# WE2_S_NS register map
Vendor: ARM Ltd.; Series: ARMv8.1-M Mainline; File version: 1.0
CPU: CM55 r1p1, little endian, MPU, FPU, double-precision FPU, DSP, VTOR, 3 interrupt priority bits
Registers are 32-bit, read-write, reset 0x0 unless marked. A register's access mark holds for its fields unless they carry their own. Offsets are from the block's base; [hi:lo] are bit positions; {n}, {i} and the like mark numbered series.

## SYS_NVIC — Nested Vectored Interrupt Controller
Base 0xE000E100
Same registers: SYS_NVIC_NS 0xE002E100
{0x0+4i} NVIC_ISER{i} (i=0..15)
  [31:0] SETENA — Interrupt set-enable bits. For SETENA[m] in NVIC_ISERn, allows interrupt 32n+m to be accessed
{0x80+4i} NVIC_ICER{i} (i=0..15)
  [31:0] CLRENA — Interrupt clear-enable bits. For SETENA[m] in NVIC_ICERn, allows interrupt 32n + m to be accessed
{0x100+4i} NVIC_ISPR{i} (i=0..15)
  [31:0] SETPEND — Interrupt set-pending bits. For SETPEND[m] in NVIC_ISPRn, allows interrupt 32n + m to be accessed
{0x180+4i} NVIC_ICPR{i} (i=0..15)
  [31:0] CLRPEND — Interrupt clear-pending bits
{0x200+4i} NVIC_IABR{i} (i=0..15)
  [31:0] ACTIVE — Active state bits. For ACTIVE[m] in NVIC_IABRn, indicates the active state for interrupt 32n+m
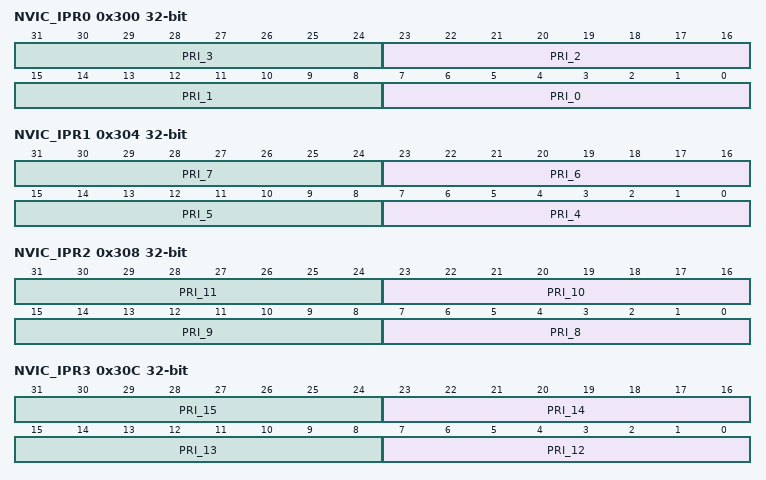
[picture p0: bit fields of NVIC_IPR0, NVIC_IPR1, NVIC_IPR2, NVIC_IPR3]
0x300 NVIC_IPR0
  [8n+7:8n] PRI_{n} (n=0..3)
0x304 NVIC_IPR1
  [8n-25:8n-32] PRI_{n} (n=4..7)
0x308 NVIC_IPR2
  [8n-57:8n-64] PRI_{n} (n=8..11)
0x30C NVIC_IPR3
  [8n-89:8n-96] PRI_{n} (n=12..15)
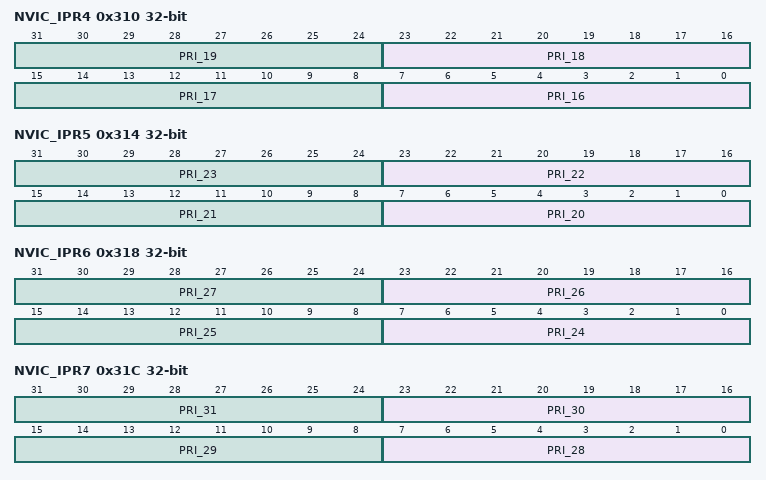
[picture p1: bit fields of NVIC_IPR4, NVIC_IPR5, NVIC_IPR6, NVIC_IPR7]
0x310 NVIC_IPR4
  [8n-121:8n-128] PRI_{n} (n=16..19)
0x314 NVIC_IPR5
  [8n-153:8n-160] PRI_{n} (n=20..23)
0x318 NVIC_IPR6
  [8n-185:8n-192] PRI_{n} (n=24..27)
0x31C NVIC_IPR7
  [8n-217:8n-224] PRI_{n} (n=28..31)
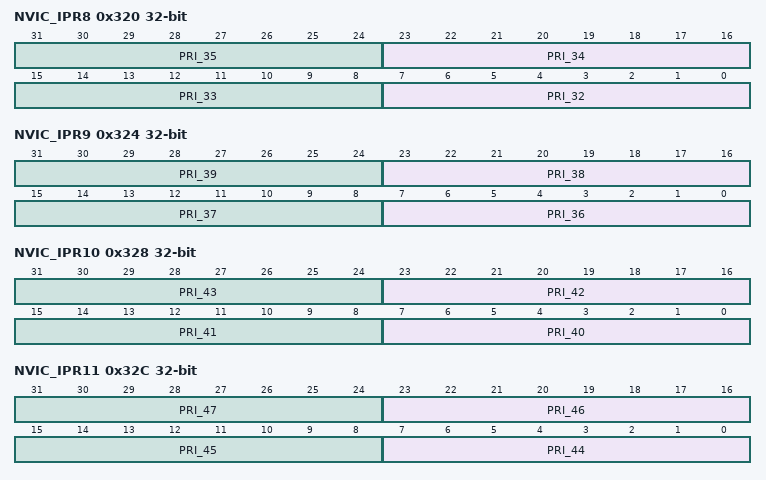
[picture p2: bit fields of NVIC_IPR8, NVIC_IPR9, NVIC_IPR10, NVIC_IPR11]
0x320 NVIC_IPR8
  [8n-249:8n-256] PRI_{n} (n=32..35)
0x324 NVIC_IPR9
  [8n-281:8n-288] PRI_{n} (n=36..39)
0x328 NVIC_IPR10
  [8n-313:8n-320] PRI_{n} (n=40..43)
0x32C NVIC_IPR11
  [8n-345:8n-352] PRI_{n} (n=44..47)
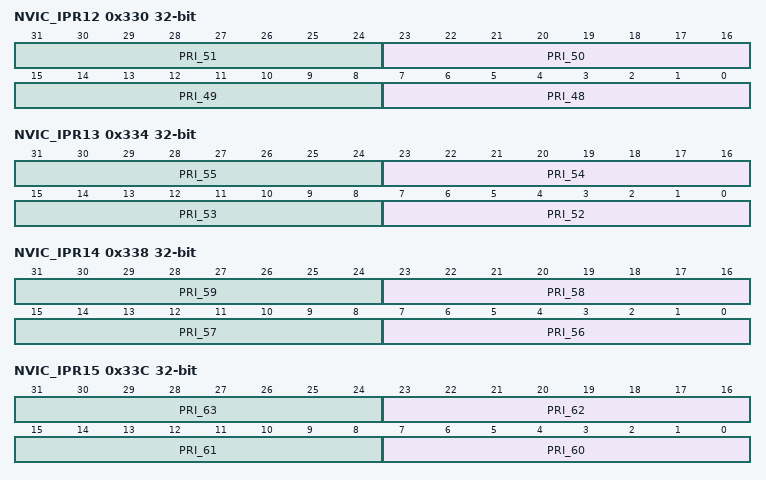
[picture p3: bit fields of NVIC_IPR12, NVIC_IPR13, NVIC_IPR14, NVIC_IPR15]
0x330 NVIC_IPR12
  [8n-377:8n-384] PRI_{n} (n=48..51)
0x334 NVIC_IPR13
  [8n-409:8n-416] PRI_{n} (n=52..55)
0x338 NVIC_IPR14
  [8n-441:8n-448] PRI_{n} (n=56..59)
0x33C NVIC_IPR15
  [8n-473:8n-480] PRI_{n} (n=60..63)
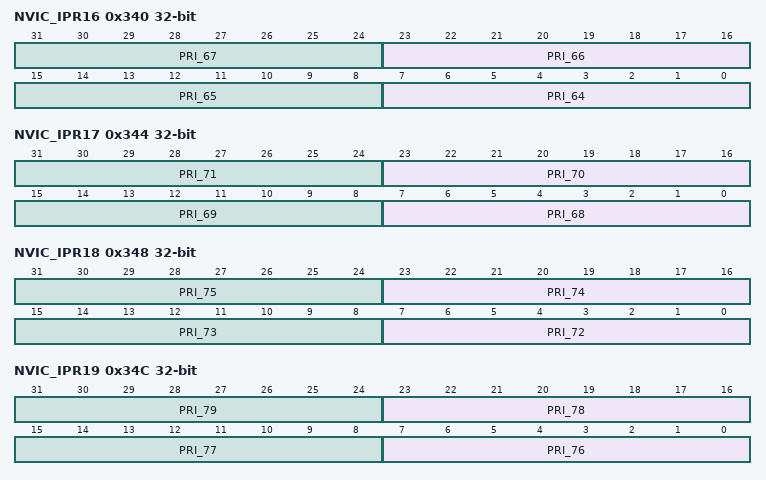
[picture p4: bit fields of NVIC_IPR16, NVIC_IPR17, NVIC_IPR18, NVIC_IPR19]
0x340 NVIC_IPR16
  [8n-505:8n-512] PRI_{n} (n=64..67)
0x344 NVIC_IPR17
  [8n-537:8n-544] PRI_{n} (n=68..71)
0x348 NVIC_IPR18
  [8n-569:8n-576] PRI_{n} (n=72..75)
0x34C NVIC_IPR19
  [8n-601:8n-608] PRI_{n} (n=76..79)
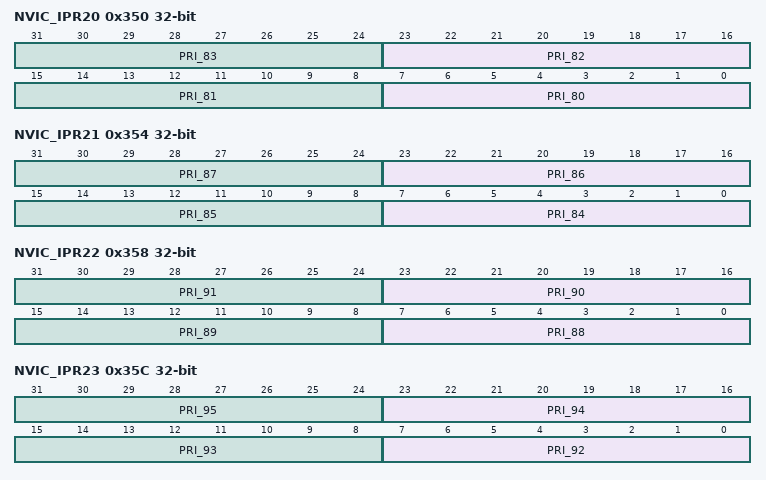
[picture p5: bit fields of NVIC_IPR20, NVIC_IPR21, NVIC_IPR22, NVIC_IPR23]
0x350 NVIC_IPR20
  [8n-633:8n-640] PRI_{n} (n=80..83)
0x354 NVIC_IPR21
  [8n-665:8n-672] PRI_{n} (n=84..87)
0x358 NVIC_IPR22
  [8n-697:8n-704] PRI_{n} (n=88..91)
0x35C NVIC_IPR23
  [8n-729:8n-736] PRI_{n} (n=92..95)
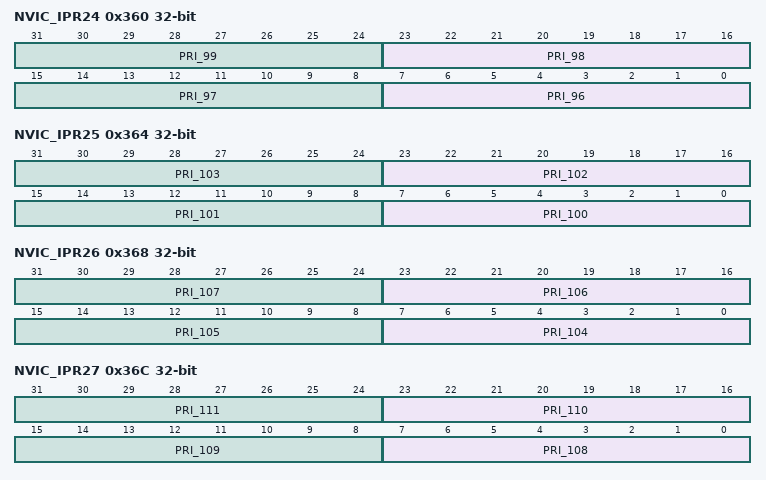
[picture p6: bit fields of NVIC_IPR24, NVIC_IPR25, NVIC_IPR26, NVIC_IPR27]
0x360 NVIC_IPR24
  [8n-761:8n-768] PRI_{n} (n=96..99)
0x364 NVIC_IPR25
  [8n-793:8n-800] PRI_{n} (n=100..103)
0x368 NVIC_IPR26
  [8n-825:8n-832] PRI_{n} (n=104..107)
0x36C NVIC_IPR27
  [8n-857:8n-864] PRI_{n} (n=108..111)
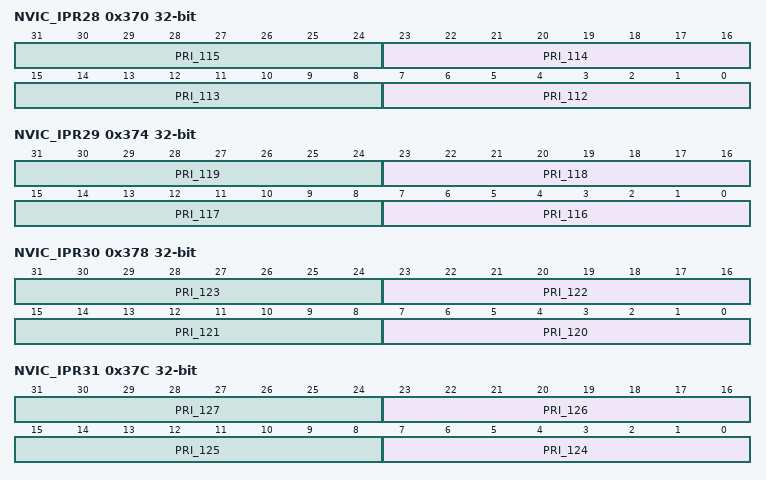
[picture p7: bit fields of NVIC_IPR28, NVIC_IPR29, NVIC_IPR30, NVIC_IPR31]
0x370 NVIC_IPR28
  [8n-889:8n-896] PRI_{n} (n=112..115)
0x374 NVIC_IPR29
  [8n-921:8n-928] PRI_{n} (n=116..119)
0x378 NVIC_IPR30
  [8n-953:8n-960] PRI_{n} (n=120..123)
0x37C NVIC_IPR31
  [8n-985:8n-992] PRI_{n} (n=124..127)
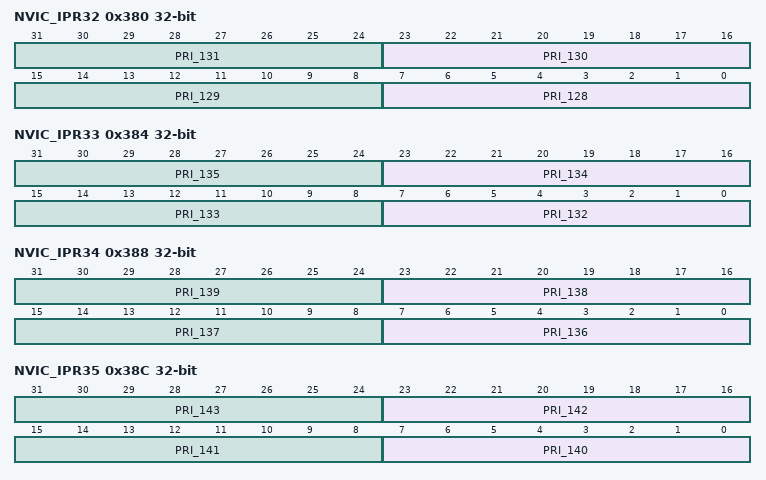
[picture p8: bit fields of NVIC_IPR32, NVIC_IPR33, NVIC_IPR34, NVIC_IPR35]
0x380 NVIC_IPR32
  [8n-1017:8n-1024] PRI_{n} (n=128..131)
0x384 NVIC_IPR33
  [8n-1049:8n-1056] PRI_{n} (n=132..135)
0x388 NVIC_IPR34
  [8n-1081:8n-1088] PRI_{n} (n=136..139)
0x38C NVIC_IPR35
  [8n-1113:8n-1120] PRI_{n} (n=140..143)
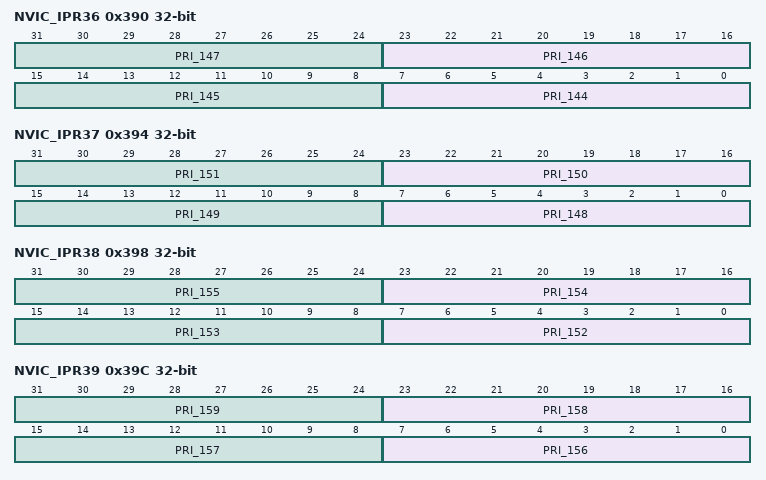
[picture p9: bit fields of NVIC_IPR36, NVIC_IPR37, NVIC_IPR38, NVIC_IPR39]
0x390 NVIC_IPR36
  [8n-1145:8n-1152] PRI_{n} (n=144..147)
0x394 NVIC_IPR37
  [8n-1177:8n-1184] PRI_{n} (n=148..151)
0x398 NVIC_IPR38
  [8n-1209:8n-1216] PRI_{n} (n=152..155)
0x39C NVIC_IPR39
  [8n-1241:8n-1248] PRI_{n} (n=156..159)
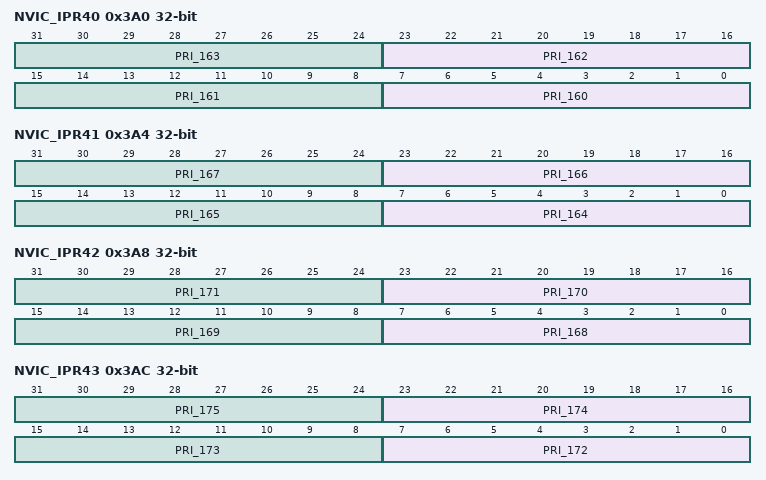
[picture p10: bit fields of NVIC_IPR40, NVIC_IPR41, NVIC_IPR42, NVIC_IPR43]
0x3A0 NVIC_IPR40
  [8n-1273:8n-1280] PRI_{n} (n=160..163)
0x3A4 NVIC_IPR41
  [8n-1305:8n-1312] PRI_{n} (n=164..167)
0x3A8 NVIC_IPR42
  [8n-1337:8n-1344] PRI_{n} (n=168..171)
0x3AC NVIC_IPR43
  [8n-1369:8n-1376] PRI_{n} (n=172..175)
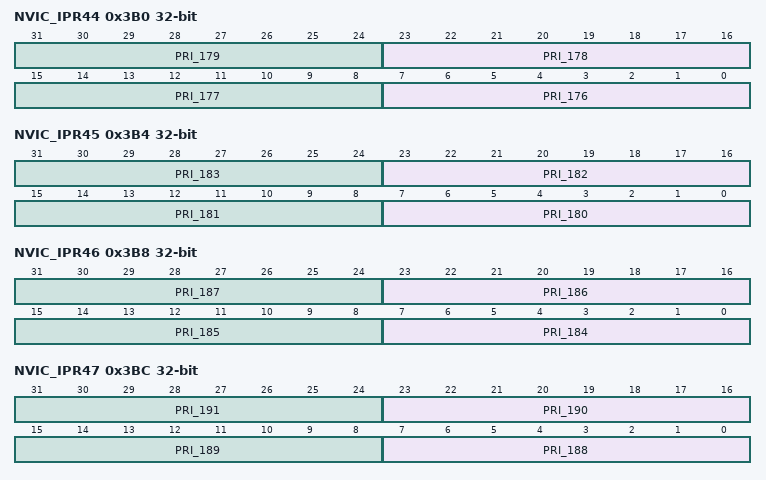
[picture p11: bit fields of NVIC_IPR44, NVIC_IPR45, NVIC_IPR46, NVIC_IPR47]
0x3B0 NVIC_IPR44
  [8n-1401:8n-1408] PRI_{n} (n=176..179)
0x3B4 NVIC_IPR45
  [8n-1433:8n-1440] PRI_{n} (n=180..183)
0x3B8 NVIC_IPR46
  [8n-1465:8n-1472] PRI_{n} (n=184..187)
0x3BC NVIC_IPR47
  [8n-1497:8n-1504] PRI_{n} (n=188..191)
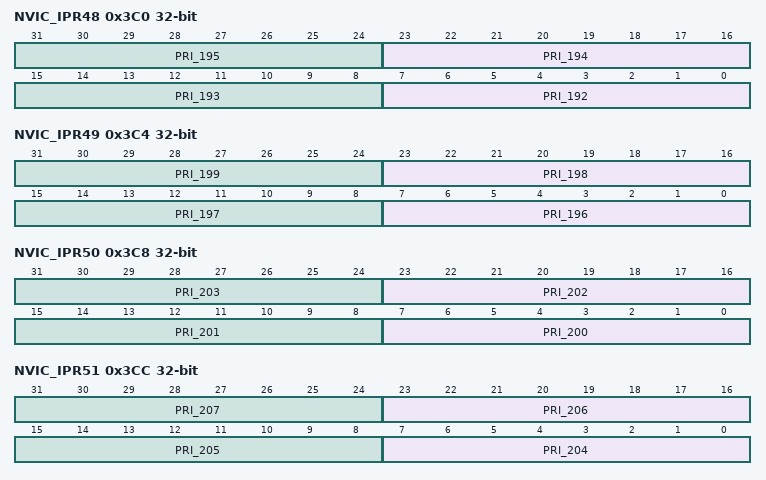
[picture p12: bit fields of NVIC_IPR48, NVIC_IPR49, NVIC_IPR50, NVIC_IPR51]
0x3C0 NVIC_IPR48
  [8n-1529:8n-1536] PRI_{n} (n=192..195)
0x3C4 NVIC_IPR49
  [8n-1561:8n-1568] PRI_{n} (n=196..199)
0x3C8 NVIC_IPR50
  [8n-1593:8n-1600] PRI_{n} (n=200..203)
0x3CC NVIC_IPR51
  [8n-1625:8n-1632] PRI_{n} (n=204..207)
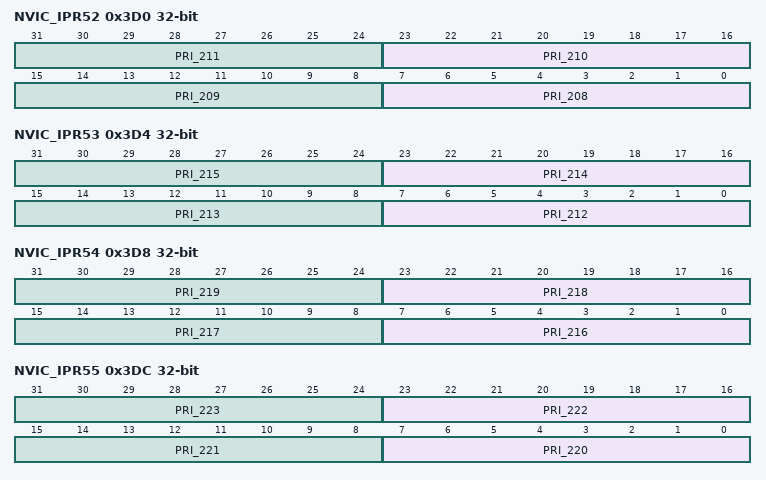
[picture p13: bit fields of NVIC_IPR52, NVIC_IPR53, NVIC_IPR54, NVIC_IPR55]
0x3D0 NVIC_IPR52
  [8n-1657:8n-1664] PRI_{n} (n=208..211)
0x3D4 NVIC_IPR53
  [8n-1689:8n-1696] PRI_{n} (n=212..215)
0x3D8 NVIC_IPR54
  [8n-1721:8n-1728] PRI_{n} (n=216..219)
0x3DC NVIC_IPR55
  [8n-1753:8n-1760] PRI_{n} (n=220..223)
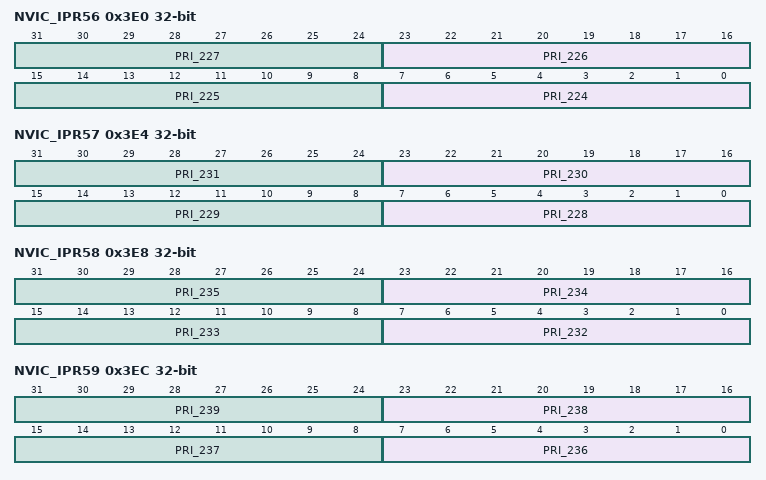
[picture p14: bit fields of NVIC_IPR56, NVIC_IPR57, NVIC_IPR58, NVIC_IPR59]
0x3E0 NVIC_IPR56
  [8n-1785:8n-1792] PRI_{n} (n=224..227)
0x3E4 NVIC_IPR57
  [8n-1817:8n-1824] PRI_{n} (n=228..231)
0x3E8 NVIC_IPR58
  [8n-1849:8n-1856] PRI_{n} (n=232..235)
0x3EC NVIC_IPR59
  [8n-1881:8n-1888] PRI_{n} (n=236..239)
0x3F0 NVIC_IPR60
  [8n-1913:8n-1920] PRI_{n} (n=240..243)
0x3F4 NVIC_IPR61
  [8n-1945:8n-1952] PRI_{n} (n=244..247)
0x3F8 NVIC_IPR62
  [8n-1977:8n-1984] PRI_{n} (n=248..251)
0x3FC NVIC_IPR63
  [8n-2009:8n-2016] PRI_{n} (n=252..255)
0x400 NVIC_IPR64
  [8n-2041:8n-2048] PRI_{n} (n=256..259)
0x404 NVIC_IPR65
  [8n-2073:8n-2080] PRI_{n} (n=260..263)
0x408 NVIC_IPR66
  [8n-2105:8n-2112] PRI_{n} (n=264..267)
0x40C NVIC_IPR67
  [8n-2137:8n-2144] PRI_{n} (n=268..271)
0x410 NVIC_IPR68
  [8n-2169:8n-2176] PRI_{n} (n=272..275)
0x414 NVIC_IPR69
  [8n-2201:8n-2208] PRI_{n} (n=276..279)
0x418 NVIC_IPR70
  [8n-2233:8n-2240] PRI_{n} (n=280..283)
0x41C NVIC_IPR71
  [8n-2265:8n-2272] PRI_{n} (n=284..287)
0x420 NVIC_IPR72
  [8n-2297:8n-2304] PRI_{n} (n=288..291)
0x424 NVIC_IPR73
  [8n-2329:8n-2336] PRI_{n} (n=292..295)
0x428 NVIC_IPR74
  [8n-2361:8n-2368] PRI_{n} (n=296..299)
0x42C NVIC_IPR75
  [8n-2393:8n-2400] PRI_{n} (n=300..303)
0x430 NVIC_IPR76
  [8n-2425:8n-2432] PRI_{n} (n=304..307)
0x434 NVIC_IPR77
  [8n-2457:8n-2464] PRI_{n} (n=308..311)
0x438 NVIC_IPR78
  [8n-2489:8n-2496] PRI_{n} (n=312..315)
0x43C NVIC_IPR79
  [8n-2521:8n-2528] PRI_{n} (n=316..319)
0x440 NVIC_IPR80
  [8n-2553:8n-2560] PRI_{n} (n=320..323)
0x444 NVIC_IPR81
  [8n-2585:8n-2592] PRI_{n} (n=324..327)
0x448 NVIC_IPR82
  [8n-2617:8n-2624] PRI_{n} (n=328..331)
0x44C NVIC_IPR83
  [8n-2649:8n-2656] PRI_{n} (n=332..335)
0x450 NVIC_IPR84
  [8n-2681:8n-2688] PRI_{n} (n=336..339)
0x454 NVIC_IPR85
  [8n-2713:8n-2720] PRI_{n} (n=340..343)
0x458 NVIC_IPR86
  [8n-2745:8n-2752] PRI_{n} (n=344..347)
0x45C NVIC_IPR87
  [8n-2777:8n-2784] PRI_{n} (n=348..351)
0x460 NVIC_IPR88
  [8n-2809:8n-2816] PRI_{n} (n=352..355)
0x464 NVIC_IPR89
  [8n-2841:8n-2848] PRI_{n} (n=356..359)
0x468 NVIC_IPR90
  [8n-2873:8n-2880] PRI_{n} (n=360..363)
0x46C NVIC_IPR91
  [8n-2905:8n-2912] PRI_{n} (n=364..367)
0x470 NVIC_IPR92
  [8n-2937:8n-2944] PRI_{n} (n=368..371)
0x474 NVIC_IPR93
  [8n-2969:8n-2976] PRI_{n} (n=372..375)
0x478 NVIC_IPR94
  [8n-3001:8n-3008] PRI_{n} (n=376..379)
0x47C NVIC_IPR95
  [8n-3033:8n-3040] PRI_{n} (n=380..383)
0x480 NVIC_IPR96
  [8n-3065:8n-3072] PRI_{n} (n=384..387)
0x484 NVIC_IPR97
  [8n-3097:8n-3104] PRI_{n} (n=388..391)
0x488 NVIC_IPR98
  [8n-3129:8n-3136] PRI_{n} (n=392..395)
0x48C NVIC_IPR99
  [8n-3161:8n-3168] PRI_{n} (n=396..399)
0x490 NVIC_IPR100
  [8n-3193:8n-3200] PRI_{n} (n=400..403)
0x494 NVIC_IPR101
  [8n-3225:8n-3232] PRI_{n} (n=404..407)
0x498 NVIC_IPR102
  [8n-3257:8n-3264] PRI_{n} (n=408..411)
0x49C NVIC_IPR103
  [8n-3289:8n-3296] PRI_{n} (n=412..415)
0x4A0 NVIC_IPR104
  [8n-3321:8n-3328] PRI_{n} (n=416..419)
0x4A4 NVIC_IPR105
  [8n-3353:8n-3360] PRI_{n} (n=420..423)
0x4A8 NVIC_IPR106
  [8n-3385:8n-3392] PRI_{n} (n=424..427)
0x4AC NVIC_IPR107
  [8n-3417:8n-3424] PRI_{n} (n=428..431)
0x4B0 NVIC_IPR108
  [8n-3449:8n-3456] PRI_{n} (n=432..435)
0x4B4 NVIC_IPR109
  [8n-3481:8n-3488] PRI_{n} (n=436..439)
0x4B8 NVIC_IPR110
  [8n-3513:8n-3520] PRI_{n} (n=440..443)
0x4BC NVIC_IPR111
  [8n-3545:8n-3552] PRI_{n} (n=444..447)
0x4C0 NVIC_IPR112
  [8n-3577:8n-3584] PRI_{n} (n=448..451)
0x4C4 NVIC_IPR113
  [8n-3609:8n-3616] PRI_{n} (n=452..455)
0x4C8 NVIC_IPR114
  [8n-3641:8n-3648] PRI_{n} (n=456..459)
0x4CC NVIC_IPR115
  [8n-3673:8n-3680] PRI_{n} (n=460..463)
0x4D0 NVIC_IPR116
  [8n-3705:8n-3712] PRI_{n} (n=464..467)
0x4D4 NVIC_IPR117
  [8n-3737:8n-3744] PRI_{n} (n=468..471)
0x4D8 NVIC_IPR118
  [8n-3769:8n-3776] PRI_{n} (n=472..475)
0x4DC NVIC_IPR119
  [8n-3801:8n-3808] PRI_{n} (n=476..479)
